VERSION ""

NS_ :

BS_:

BU_: Motor

BO_ 0 New_Message_5: 8 Vector__XXX
 SG_ New_Signal_13 : 7|8@1+ (1,0) [0|0] "" Vector__XXX

BO_ 336 Motor_List2: 8 Vector__XXX
 SG_ Signal_4 : 32|32@1- (1,0) [0|0] "" Vector__XXX
 SG_ Signal_3 : 0|32@1- (1,0) [0|0] "" Vector__XXX

BO_ 325 Motor_List1: 8 Vector__XXX
 SG_ Signal_2 : 32|32@1- (1,0) [0|0] "" Vector__XXX
 SG_ Signal_1 : 0|32@1- (1,0) [0|0] "" Vector__XXX

BO_ 290 Motor_CMD: 8 Vector__XXX
 SG_ Motor_Run_Rpm : 23|16@0- (1,0) [0|0] "" Vector__XXX
 SG_ Motor_Run_Req : 7|1@0+ (1,0) [0|0] "" Vector__XXX

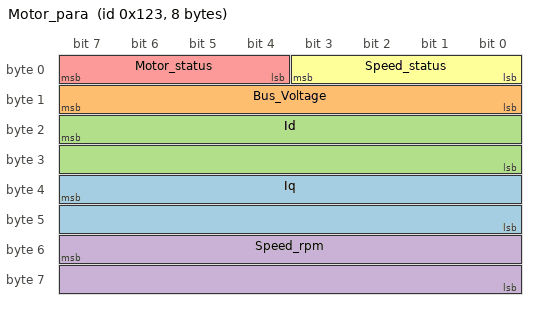
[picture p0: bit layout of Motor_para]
BO_ 291 Motor_para: 8 Vector__XXX
 SG_ Iq : 39|16@0- (0.001,0) [-30|30] "" Vector__XXX
 SG_ Bus_Voltage : 15|8@0+ (1,0) [0|200] "" Vector__XXX
 SG_ Id : 23|16@0- (0.001,0) [-30|30] "" Vector__XXX
 SG_ Speed_rpm : 55|16@0- (0.5,0) [-10000|10000] "" Vector__XXX
 SG_ Motor_status : 7|4@0+ (1,0) [0|8] "" Vector__XXX
 SG_ Speed_status : 3|4@0+ (1,0) [0|8] "" Vector__XXX

BA_DEF_ SG_  "GenSigSendType" ENUM  "Cyclic","OnWrite","OnWriteWithRepetition","OnChange","OnChangeWithRepetition","IfActive","IfActiveWithRepetition","NoSigSendType";
BA_DEF_ BO_  "GenMsgSendType" ENUM  "Cyclic","not_used","not_used","not_used","not_used","Cyclic","not_used","IfActive","NoMsgSendType";
BA_DEF_ BU_  "NmStationAddress" HEX 0 0;
BA_DEF_  "DBName" STRING ;
BA_DEF_  "BusType" STRING ;
BA_DEF_DEF_  "GenSigSendType" "Cyclic";
BA_DEF_DEF_  "GenMsgSendType" "NoMsgSendType";
BA_DEF_DEF_  "NmStationAddress" 0;
BA_DEF_DEF_  "DBName" "";
BA_DEF_DEF_  "BusType" "CAN";
BA_ "DBName" "Test";
BA_ "NmStationAddress" BU_ Motor 1;
SIG_VALTYPE_ 336 Signal_4 : 1;
SIG_VALTYPE_ 336 Signal_3 : 1;
SIG_VALTYPE_ 325 Signal_2 : 1;
SIG_VALTYPE_ 325 Signal_1 : 1;
